# STM32H7B3 register map
File version: 3.3
CPU: CM7 r0p1, little endian, MPU, FPU, 4 interrupt priority bits
Registers are 32-bit, read-write, reset 0x0 unless marked. A register's access mark holds for its fields unless they carry their own. Offsets are from the block's base; [hi:lo] are bit positions; {n}, {i} and the like mark numbered series.

## CAN_CCU — FDCAN1
Base 0x4000A800
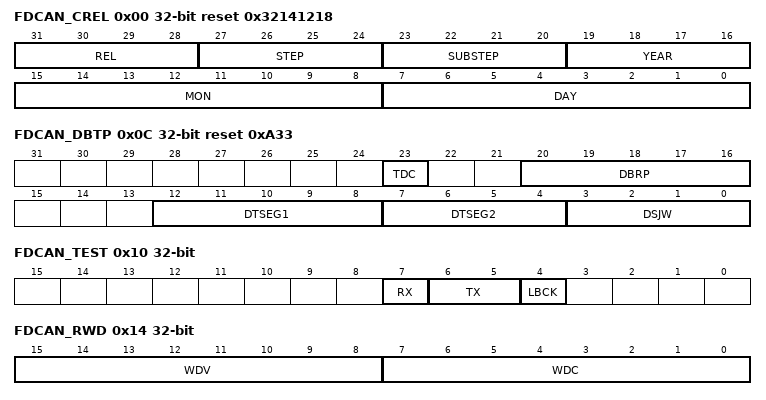
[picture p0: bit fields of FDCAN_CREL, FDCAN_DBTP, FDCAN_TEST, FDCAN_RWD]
0x00 FDCAN_CREL ro reset 0x32141218 — FDCAN Core Release Register
  [31:28] REL — Core release
  [27:24] STEP — Step of Core release
  [23:20] SUBSTEP — Sub-step of Core release
  [19:16] YEAR — Timestamp Year
  [15:8] MON — Timestamp Month
  [7:0] DAY — Timestamp Day
0x04 FDCAN_ENDN ro reset 0x87654321 — FDCAN Core Release Register
  [31:0] ETV — Endiannes Test Value
0x0C FDCAN_DBTP ro reset 0xA33 — FDCAN Data Bit Timing and Prescaler Register
  [23] TDC — Transceiver Delay Compensation
  [20:16] DBRP — Data BIt Rate Prescaler
  [12:8] DTSEG1 — Data time segment after sample point
  [7:4] DTSEG2 — Data time segment after sample point
  [3:0] DSJW — Synchronization Jump Width
0x10 FDCAN_TEST ro
  [7] RX — Control of Transmit Pin
  [6:5] TX — Loop Back mode
  [4] LBCK — Loop Back mode
0x14 FDCAN_RWD ro — FDCAN RAM Watchdog Register
  [15:8] WDV — Watchdog value
  [7:0] WDC — Watchdog configuration
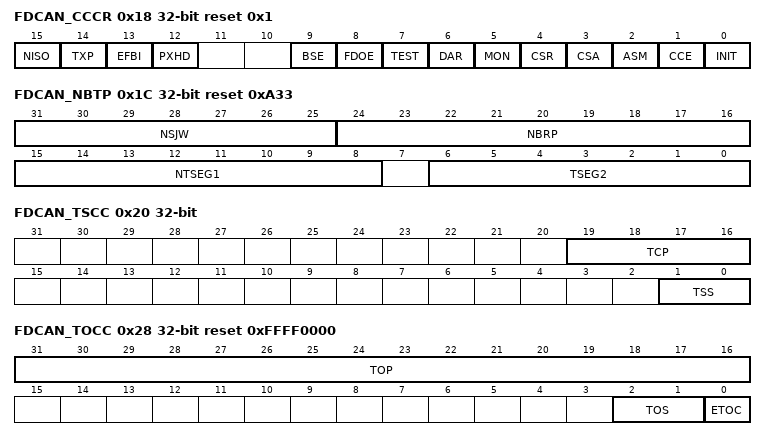
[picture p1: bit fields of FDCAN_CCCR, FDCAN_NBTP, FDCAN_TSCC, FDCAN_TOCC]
0x18 FDCAN_CCCR reset 0x1 — FDCAN CC Control Register
  [15] NISO — Non ISO Operation
  [14] TXP
  [13] EFBI — Edge Filtering during Bus Integration
  [12] PXHD — Protocol Exception Handling Disable
  [9] BSE — FDCAN Bit Rate Switching
  [8] FDOE — FD Operation Enable
  [7] TEST — Test Mode Enable
  [6] DAR — Disable Automatic Retransmission
  [5] MON — Bus Monitoring Mode
  [4] CSR — Clock Stop Request
  [3] CSA — Clock Stop Acknowledge
  [2] ASM — ASM Restricted Operation Mode
  [1] CCE — Configuration Change Enable
  [0] INIT — Initialization
0x1C FDCAN_NBTP reset 0xA33 — FDCAN Nominal Bit Timing and Prescaler Register
  [31:25] NSJW — NSJW: Nominal (Re)Synchronization Jump Width
  [24:16] NBRP — Bit Rate Prescaler
  [15:8] NTSEG1 — Nominal Time segment before sample point
  [6:0] TSEG2 — Nominal Time segment after sample point
0x20 FDCAN_TSCC — FDCAN Timestamp Counter Configuration Register
  [19:16] TCP — Timestamp Counter Prescaler
  [1:0] TSS — Timestamp Select
0x24 FDCAN_TSCV — FDCAN Timestamp Counter Value Register
  [15:0] TSC — Timestamp Counter
0x28 FDCAN_TOCC reset 0xFFFF0000 — FDCAN Timeout Counter Configuration Register
  [31:16] TOP — Timeout Period
  [2:1] TOS — Timeout Select
  [0] ETOC — Enable Timeout Counter
0x2C FDCAN_TOCV reset 0xFFFF — FDCAN Timeout Counter Value Register
  [15:0] TOC — Timeout Counter
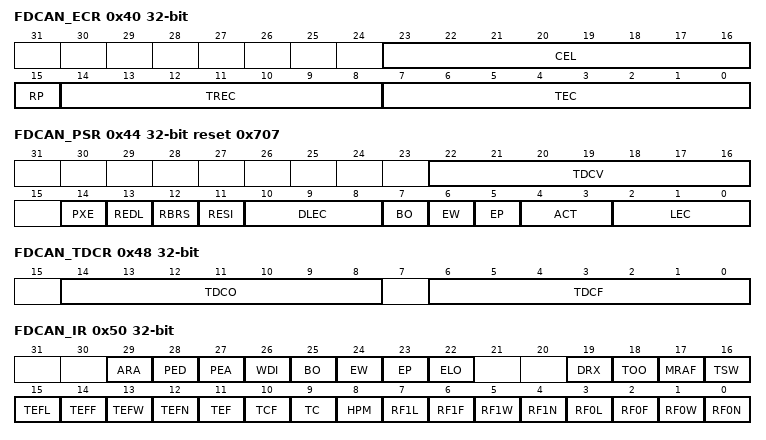
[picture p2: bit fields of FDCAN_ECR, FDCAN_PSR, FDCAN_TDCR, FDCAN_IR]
0x40 FDCAN_ECR — FDCAN Error Counter Register
  [23:16] CEL — AN Error Logging
  [15] RP — Receive Error Passive
  [14:8] TREC — Receive Error Counter
  [7:0] TEC — Transmit Error Counter
0x44 FDCAN_PSR reset 0x707 — FDCAN Protocol Status Register
  [22:16] TDCV — Transmitter Delay Compensation Value
  [14] PXE — Protocol Exception Event
  [13] REDL — Received FDCAN Message
  [12] RBRS — BRS flag of last received FDCAN Message
  [11] RESI — ESI flag of last received FDCAN Message
  [10:8] DLEC — Data Last Error Code
  [7] BO — Bus_Off Status
  [6] EW — Warning Status
  [5] EP — Error Passive
  [4:3] ACT — Activity
  [2:0] LEC — Last Error Code
0x48 FDCAN_TDCR ro — FDCAN Transmitter Delay Compensation Register
  [14:8] TDCO — Transmitter Delay Compensation Offset
  [6:0] TDCF — Transmitter Delay Compensation Filter Window Length
0x50 FDCAN_IR ro — FDCAN Interrupt Register
  [29] ARA — Access to Reserved Address
  [28] PED — Protocol Error in Data Phase (Data Bit Time is used)
  [27] PEA — Protocol Error in Arbitration Phase (Nominal Bit Time is used)
  [26] WDI — Watchdog Interrupt
  [25] BO — Bus_Off Status
  [24] EW — Warning Status
  [23] EP — Error Passive
  [22] ELO — Error Logging Overflow
  [19] DRX — Message stored to Dedicated Rx Buffer
  [18] TOO — Timeout Occurred
  [17] MRAF — Message RAM Access Failure
  [16] TSW — Timestamp Wraparound
  [15] TEFL — Tx Event FIFO Element Lost
  [14] TEFF — Tx Event FIFO Full
  [13] TEFW — Tx Event FIFO Watermark Reached
  [12] TEFN — Tx Event FIFO New Entry
  [11] TEF — Tx FIFO Empty
  [10] TCF — Transmission Cancellation Finished
  [9] TC — Transmission Completed
  [8] HPM — High Priority Message
  [7] RF1L — Rx FIFO 1 Message Lost
  [6] RF1F — Rx FIFO 1 Watermark Reached
  [5] RF1W — Rx FIFO 1 Watermark Reached
  [4] RF1N — Rx FIFO 1 New Message
  [3] RF0L — Rx FIFO 0 Message Lost
  [2] RF0F — Rx FIFO 0 Full
  [1] RF0W — Rx FIFO 0 Full
  [0] RF0N — Rx FIFO 0 New Message
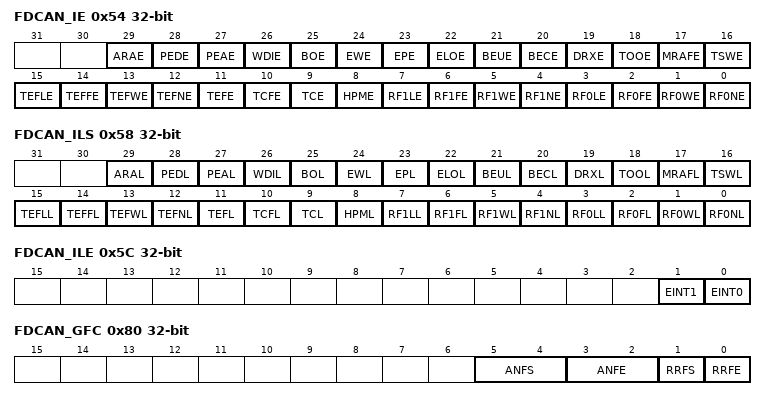
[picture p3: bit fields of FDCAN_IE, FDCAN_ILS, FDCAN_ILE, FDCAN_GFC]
0x54 FDCAN_IE — FDCAN Interrupt Enable Register
  [29] ARAE — Access to Reserved Address Enable
  [28] PEDE — Protocol Error in Data Phase Enable
  [27] PEAE — Protocol Error in Arbitration Phase Enable
  [26] WDIE — Watchdog Interrupt Enable
  [25] BOE — Bus_Off Status Enable
  [24] EWE — Warning Status Enable
  [23] EPE — Error Passive Enable
  [22] ELOE — Error Logging Overflow Enable
  [21] BEUE — Bit Error Uncorrected Interrupt Enable
  [20] BECE — Bit Error Corrected Interrupt Enable
  [19] DRXE — Message stored to Dedicated Rx Buffer Enable
  [18] TOOE — Timeout Occurred Enable
  [17] MRAFE — Message RAM Access Failure Enable
  [16] TSWE — Timestamp Wraparound Enable
  [15] TEFLE — Tx Event FIFO Element Lost Enable
  [14] TEFFE — Tx Event FIFO Full Enable
  [13] TEFWE — Tx Event FIFO Watermark Reached Enable
  [12] TEFNE — Tx Event FIFO New Entry Enable
  [11] TEFE — Tx FIFO Empty Enable
  [10] TCFE — Transmission Cancellation Finished Enable
  [9] TCE — Transmission Completed Enable
  [8] HPME — High Priority Message Enable
  [7] RF1LE — Rx FIFO 1 Message Lost Enable
  [6] RF1FE — Rx FIFO 1 Watermark Reached Enable
  [5] RF1WE — Rx FIFO 1 Watermark Reached Enable
  [4] RF1NE — Rx FIFO 1 New Message Enable
  [3] RF0LE — Rx FIFO 0 Message Lost Enable
  [2] RF0FE — Rx FIFO 0 Full Enable
  [1] RF0WE — Rx FIFO 0 Full Enable
  [0] RF0NE — Rx FIFO 0 New Message Enable
0x58 FDCAN_ILS ro — FDCAN Interrupt Line Select Register
  [29] ARAL — Access to Reserved Address Line
  [28] PEDL — Protocol Error in Data Phase Line
  [27] PEAL — Protocol Error in Arbitration Phase Line
  [26] WDIL — Watchdog Interrupt Line
  [25] BOL — Bus_Off Status
  [24] EWL — Warning Status Interrupt Line
  [23] EPL — Error Passive Interrupt Line
  [22] ELOL — Error Logging Overflow Interrupt Line
  [21] BEUL — Bit Error Uncorrected Interrupt Line
  [20] BECL — Bit Error Corrected Interrupt Line
  [19] DRXL — Message stored to Dedicated Rx Buffer Interrupt Line
  [18] TOOL — Timeout Occurred Interrupt Line
  [17] MRAFL — Message RAM Access Failure Interrupt Line
  [16] TSWL — Timestamp Wraparound Interrupt Line
  [15] TEFLL — Tx Event FIFO Element Lost Interrupt Line
  [14] TEFFL — Tx Event FIFO Full Interrupt Line
  [13] TEFWL — Tx Event FIFO Watermark Reached Interrupt Line
  [12] TEFNL — Tx Event FIFO New Entry Interrupt Line
  [11] TEFL — Tx FIFO Empty Interrupt Line
  [10] TCFL — Transmission Cancellation Finished Interrupt Line
  [9] TCL — Transmission Completed Interrupt Line
  [8] HPML — High Priority Message Interrupt Line
  [7] RF1LL — Rx FIFO 1 Message Lost Interrupt Line
  [6] RF1FL — Rx FIFO 1 Full Interrupt Line
  [5] RF1WL — Rx FIFO 1 Watermark Reached Interrupt Line
  [4] RF1NL — Rx FIFO 1 New Message Interrupt Line
  [3] RF0LL — Rx FIFO 0 Message Lost Interrupt Line
  [2] RF0FL — Rx FIFO 0 Full Interrupt Line
  [1] RF0WL — Rx FIFO 0 Watermark Reached Interrupt Line
  [0] RF0NL — Rx FIFO 0 New Message Interrupt Line
0x5C FDCAN_ILE — FDCAN Interrupt Line Enable Register
  [1] EINT1 — Enable Interrupt Line 1
  [0] EINT0 — Enable Interrupt Line 0
0x80 FDCAN_GFC — FDCAN Global Filter Configuration Register
  [5:4] ANFS — Accept Non-matching Frames Standard
  [3:2] ANFE — Accept Non-matching Frames Extended
  [1] RRFS — Reject Remote Frames Standard
  [0] RRFE — Reject Remote Frames Extended
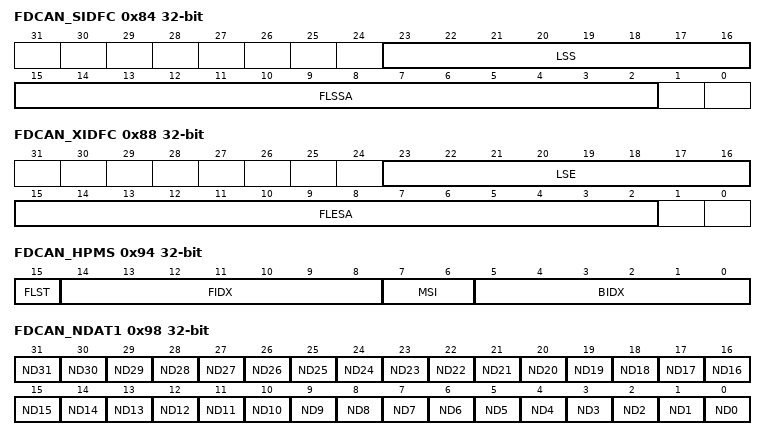
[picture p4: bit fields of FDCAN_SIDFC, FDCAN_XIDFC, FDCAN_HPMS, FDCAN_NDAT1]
0x84 FDCAN_SIDFC — FDCAN Standard ID Filter Configuration Register
  [23:16] LSS — List Size Standard
  [15:2] FLSSA — Filter List Standard Start Address
0x88 FDCAN_XIDFC — FDCAN Extended ID Filter Configuration Register
  [23:16] LSE — List Size Extended
  [15:2] FLESA — Filter List Standard Start Address
0x90 FDCAN_XIDAM — FDCAN Extended ID and Mask Register
  [28:0] EIDM — Extended ID Mask
0x94 FDCAN_HPMS ro — FDCAN High Priority Message Status Register
  [15] FLST — Filter List
  [14:8] FIDX — Filter Index
  [7:6] MSI — Message Storage Indicator
  [5:0] BIDX — Buffer Index
0x98 FDCAN_NDAT1 ro — FDCAN New Data 1 Register
  [n] ND{n} (n=0..31) — New data
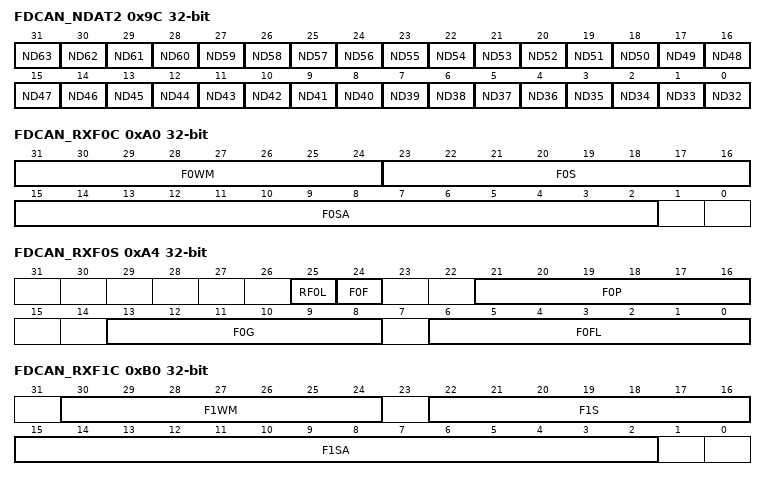
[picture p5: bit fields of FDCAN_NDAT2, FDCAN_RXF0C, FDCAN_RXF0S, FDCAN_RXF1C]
0x9C FDCAN_NDAT2 ro — FDCAN New Data 2 Register
  [n-32] ND{n} (n=32..63) — New data
0xA0 FDCAN_RXF0C — FDCAN Rx FIFO 0 Configuration Register
  [31:24] F0WM — FIFO 0 Watermark
  [23:16] F0S — Rx FIFO 0 Size
  [15:2] F0SA — Rx FIFO 0 Start Address
0xA4 FDCAN_RXF0S — FDCAN Rx FIFO 0 Status Register
  [25] RF0L — Rx FIFO 0 Message Lost
  [24] F0F — Rx FIFO 0 Full
  [21:16] F0P — Rx FIFO 0 Put Index
  [13:8] F0G — Rx FIFO 0 Get Index
  [6:0] F0FL — Rx FIFO 0 Fill Level
0xA8 FDCAN_RXF0A — CAN Rx FIFO 0 Acknowledge Register
  [5:0] FA01 — Rx FIFO 0 Acknowledge Index
0xAC FDCAN_RXBC — FDCAN Rx Buffer Configuration Register
  [15:2] RBSA — Rx Buffer Start Address
0xB0 FDCAN_RXF1C — FDCAN Rx FIFO 1 Configuration Register
  [30:24] F1WM — Rx FIFO 1 Watermark
  [22:16] F1S — Rx FIFO 1 Size
  [15:2] F1SA — Rx FIFO 1 Start Address
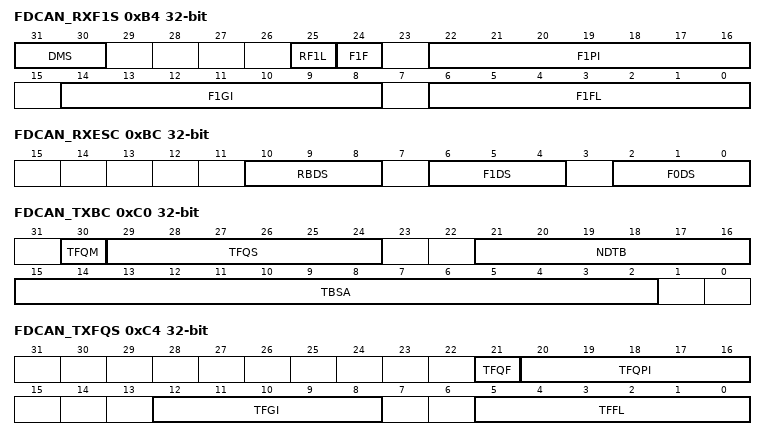
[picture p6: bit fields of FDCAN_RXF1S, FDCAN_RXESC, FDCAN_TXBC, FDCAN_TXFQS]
0xB4 FDCAN_RXF1S — FDCAN Rx FIFO 1 Status Register
  [31:30] DMS — Debug Message Status
  [25] RF1L — Rx FIFO 1 Message Lost
  [24] F1F — Rx FIFO 1 Full
  [22:16] F1PI — Rx FIFO 1 Put Index
  [14:8] F1GI — Rx FIFO 1 Get Index
  [6:0] F1FL — Rx FIFO 1 Fill Level
0xB8 FDCAN_RXF1A — FDCAN Rx FIFO 1 Acknowledge Register
  [5:0] F1AI — Rx FIFO 1 Acknowledge Index
0xBC FDCAN_RXESC — FDCAN Rx Buffer Element Size Configuration Register
  [10:8] RBDS — Rx Buffer Data Field Size:
  [6:4] F1DS — Rx FIFO 0 Data Field Size:
  [2:0] F0DS — Rx FIFO 1 Data Field Size:
0xC0 FDCAN_TXBC — FDCAN Tx Buffer Configuration Register
  [30] TFQM — Tx FIFO/Queue Mode
  [29:24] TFQS — Transmit FIFO/Queue Size
  [21:16] NDTB — Number of Dedicated Transmit Buffers
  [15:2] TBSA — Tx Buffers Start Address
0xC4 FDCAN_TXFQS ro — FDCAN Tx FIFO/Queue Status Register
  [21] TFQF — Tx FIFO/Queue Full
  [20:16] TFQPI — Tx FIFO/Queue Put Index
  [12:8] TFGI
  [5:0] TFFL — Tx FIFO Free Level
0xC8 FDCAN_TXESC — FDCAN Tx Buffer Element Size Configuration Register
  [2:0] TBDS — Tx Buffer Data Field Size:
0xCC FDCAN_TXBRP ro — FDCAN Tx Buffer Request Pending Register
  [31:0] TRP — Transmission Request Pending
0xD0 FDCAN_TXBAR — FDCAN Tx Buffer Add Request Register
  [31:0] AR — Add Request
0xD4 FDCAN_TXBCR — FDCAN Tx Buffer Cancellation Request Register
  [31:0] CR — Cancellation Request
0xD8 FDCAN_TXBTO — FDCAN Tx Buffer Transmission Occurred Register
  [31:0] TO — Transmission Occurred.
0xDC FDCAN_TXBCF ro — FDCAN Tx Buffer Cancellation Finished Register
  [31:0] CF — Cancellation Finished
0xE0 FDCAN_TXBTIE — FDCAN Tx Buffer Transmission Interrupt Enable Register
  [31:0] TIE — Transmission Interrupt Enable
0xE4 FDCAN_TXBCIE — FDCAN Tx Buffer Cancellation Finished Interrupt Enable Register
  [31:0] CF — Cancellation Finished Interrupt Enable
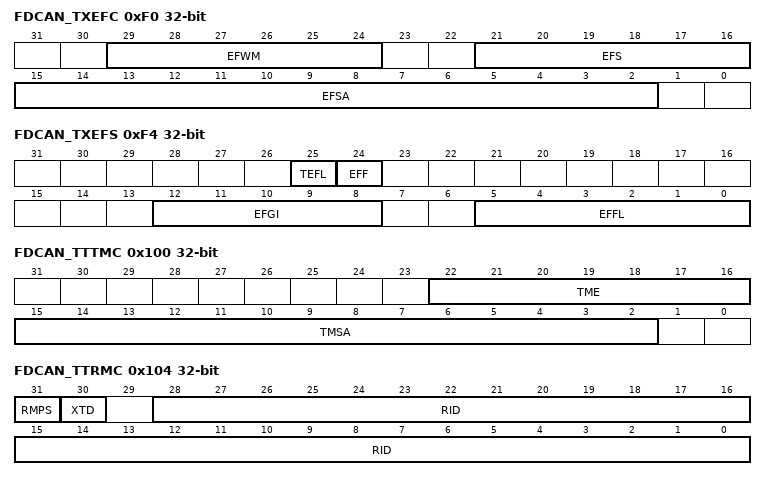
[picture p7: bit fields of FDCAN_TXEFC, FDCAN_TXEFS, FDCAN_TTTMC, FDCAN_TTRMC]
0xF0 FDCAN_TXEFC — FDCAN Tx Event FIFO Configuration Register
  [29:24] EFWM — Event FIFO Watermark
  [21:16] EFS — Event FIFO Size
  [15:2] EFSA — Event FIFO Start Address
0xF4 FDCAN_TXEFS — FDCAN Tx Event FIFO Status Register
  [25] TEFL — Tx Event FIFO Element Lost.
  [24] EFF — Event FIFO Full.
  [12:8] EFGI — Event FIFO Get Index.
  [5:0] EFFL — Event FIFO Fill Level
0xF8 FDCAN_TXEFA — FDCAN Tx Event FIFO Acknowledge Register
  [4:0] EFAI — Event FIFO Acknowledge Index
0x100 FDCAN_TTTMC — FDCAN TT Trigger Memory Configuration Register
  [22:16] TME — Trigger Memory Elements
  [15:2] TMSA — Trigger Memory Start Address
0x104 FDCAN_TTRMC — FDCAN TT Reference Message Configuration Register
  [31] RMPS — Reference Message Payload Select
  [30] XTD — Extended Identifier
  [28:0] RID — Reference Identifier.
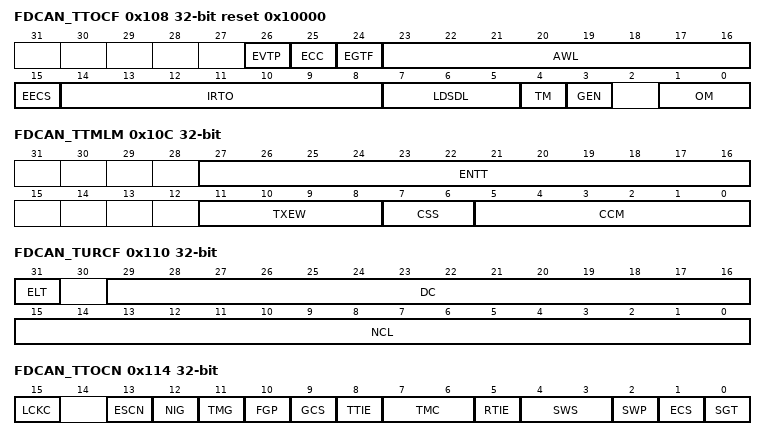
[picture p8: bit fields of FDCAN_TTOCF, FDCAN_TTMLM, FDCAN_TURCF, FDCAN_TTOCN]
0x108 FDCAN_TTOCF reset 0x10000 — FDCAN TT Operation Configuration Register
  [26] EVTP — Event Trigger Polarity
  [25] ECC — Enable Clock Calibration
  [24] EGTF — Enable Global Time Filtering
  [23:16] AWL — Application Watchdog Limit
  [15] EECS — Enable External Clock Synchronization
  [14:8] IRTO — Initial Reference Trigger Offset
  [7:5] LDSDL — LD of Synchronization Deviation Limit
  [4] TM — Time Master
  [3] GEN — Gap Enable
  [1:0] OM — Operation Mode
0x10C FDCAN_TTMLM — FDCAN TT Matrix Limits Register
  [27:16] ENTT — Expected Number of Tx Triggers
  [11:8] TXEW — Tx Enable Window
  [7:6] CSS — Cycle Start Synchronization
  [5:0] CCM — Cycle Count Max
0x110 FDCAN_TURCF — FDCAN TUR Configuration Register
  [31] ELT — Enable Local Time
  [29:16] DC — Denominator Configuration.
  [15:0] NCL — Numerator Configuration Low.
0x114 FDCAN_TTOCN — FDCAN TT Operation Control Register
  [15] LCKC — TT Operation Control Register Locked
  [13] ESCN — External Synchronization Control
  [12] NIG — Next is Gap
  [11] TMG — Time Mark Gap
  [10] FGP — Finish Gap.
  [9] GCS — Gap Control Select
  [8] TTIE — Trigger Time Mark Interrupt Pulse Enable
  [7:6] TMC — Register Time Mark Compare
  [5] RTIE — Register Time Mark Interrupt Pulse Enable
  [4:3] SWS — Stop Watch Source.
  [2] SWP — Stop Watch Polarity
  [1] ECS — External Clock Synchronization
  [0] SGT — Set Global time
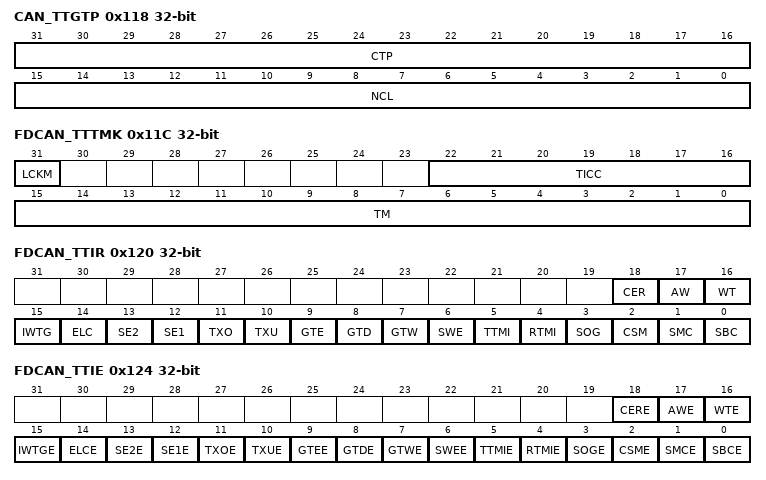
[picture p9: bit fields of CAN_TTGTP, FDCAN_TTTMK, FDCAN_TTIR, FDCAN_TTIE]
0x118 CAN_TTGTP — FDCAN TT Global Time Preset Register
  [31:16] CTP — Cycle Time Target Phase
  [15:0] NCL — Time Preset
0x11C FDCAN_TTTMK — FDCAN TT Time Mark Register
  [31] LCKM — TT Time Mark Register Locked
  [22:16] TICC — Time Mark Cycle Code
  [15:0] TM — Time Mark
0x120 FDCAN_TTIR — FDCAN TT Interrupt Register
  [18] CER — Configuration Error
  [17] AW — Application Watchdog
  [16] WT — Watch Trigger
  [15] IWTG — Initialization Watch Trigger
  [14] ELC — Error Level Changed.
  [13] SE2 — Scheduling Error 2
  [12] SE1 — Scheduling Error 1
  [11] TXO — Tx Count Overflow
  [10] TXU — Tx Count Underflow
  [9] GTE — Global Time Error
  [8] GTD — Global Time Discontinuity
  [7] GTW — Global Time Wrap
  [6] SWE — Stop Watch Event
  [5] TTMI — Trigger Time Mark Event Internal
  [4] RTMI — Register Time Mark Interrupt.
  [3] SOG — Start of Gap
  [2] CSM — Change of Synchronization Mode
  [1] SMC — Start of Matrix Cycle
  [0] SBC — Start of Basic Cycle
0x124 FDCAN_TTIE — FDCAN TT Interrupt Enable Register
  [18] CERE — Configuration Error Interrupt Enable
  [17] AWE — Application Watchdog Interrupt Enable
  [16] WTE — Watch Trigger Interrupt Enable
  [15] IWTGE — Initialization Watch Trigger Interrupt Enable
  [14] ELCE — Change Error Level Interrupt Enable
  [13] SE2E — Scheduling Error 2 Interrupt Enable
  [12] SE1E — Scheduling Error 1 Interrupt Enable
  [11] TXOE — Tx Count Overflow Interrupt Enable
  [10] TXUE — Tx Count Underflow Interrupt Enable
  [9] GTEE — Global Time Error Interrupt Enable
  [8] GTDE — Global Time Discontinuity Interrupt Enable
  [7] GTWE — Global Time Wrap Interrupt Enable
  [6] SWEE — Stop Watch Event Interrupt Enable
  [5] TTMIE — Trigger Time Mark Event Internal Interrupt Enable
  [4] RTMIE — Register Time Mark Interrupt Enable
  [3] SOGE — Start of Gap Interrupt Enable
  [2] CSME — Change of Synchronization Mode Interrupt Enable
  [1] SMCE — Start of Matrix Cycle Interrupt Enable
  [0] SBCE — Start of Basic Cycle Interrupt Enable
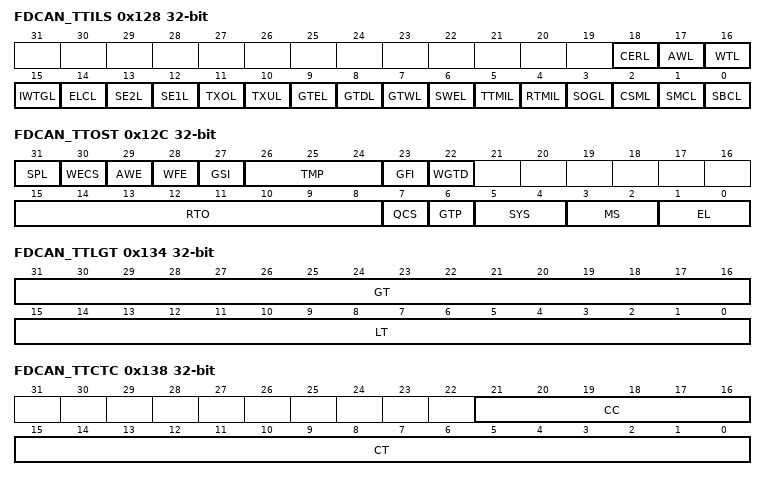
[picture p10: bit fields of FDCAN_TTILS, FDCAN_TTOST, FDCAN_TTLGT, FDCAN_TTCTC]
0x128 FDCAN_TTILS — FDCAN TT Interrupt Line Select Register
  [18] CERL — Configuration Error Interrupt Line
  [17] AWL — Application Watchdog Interrupt Line
  [16] WTL — Watch Trigger Interrupt Line
  [15] IWTGL — Initialization Watch Trigger Interrupt Line
  [14] ELCL — Change Error Level Interrupt Line
  [13] SE2L — Scheduling Error 2 Interrupt Line
  [12] SE1L — Scheduling Error 1 Interrupt Line
  [11] TXOL — Tx Count Overflow Interrupt Line
  [10] TXUL — Tx Count Underflow Interrupt Line
  [9] GTEL — Global Time Error Interrupt Line
  [8] GTDL — Global Time Discontinuity Interrupt Line
  [7] GTWL — Global Time Wrap Interrupt Line
  [6] SWEL — Stop Watch Event Interrupt Line
  [5] TTMIL — Trigger Time Mark Event Internal Interrupt Line
  [4] RTMIL — Register Time Mark Interrupt Line
  [3] SOGL — Start of Gap Interrupt Line
  [2] CSML — Change of Synchronization Mode Interrupt Line
  [1] SMCL — Start of Matrix Cycle Interrupt Line
  [0] SBCL — Start of Basic Cycle Interrupt Line
0x12C FDCAN_TTOST ro — FDCAN TT Operation Status Register
  [31] SPL — Schedule Phase Lock
  [30] WECS — Wait for External Clock Synchronization
  [29] AWE — Application Watchdog Event
  [28] WFE — Wait for Event
  [27] GSI — Gap Started Indicator.
  [26:24] TMP — Time Master Priority
  [23] GFI — Gap Finished Indicator.
  [22] WGTD — Wait for Global Time Discontinuity
  [15:8] RTO — Reference Trigger Offset
  [7] QCS — Quality of Clock Speed
  [6] GTP — Quality of Global Time Phase
  [5:4] SYS — Synchronization State
  [3:2] MS — Master State.
  [1:0] EL — Error Level
0x130 FDCAN_TURNA ro — FDCAN TUR Numerator Actual Register
  [17:0] NAV — Numerator Actual Value
0x134 FDCAN_TTLGT ro — FDCAN TT Local and Global Time Register
  [31:16] GT — Global Time
  [15:0] LT — Local Time
0x138 FDCAN_TTCTC ro — FDCAN TT Cycle Time and Count Register
  [21:16] CC — Cycle Count
  [15:0] CT — Cycle Time
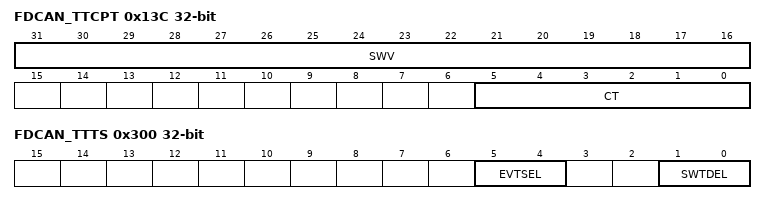
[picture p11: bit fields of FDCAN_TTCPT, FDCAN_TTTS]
0x13C FDCAN_TTCPT ro — FDCAN TT Capture Time Register
  [31:16] SWV — Stop Watch Value
  [5:0] CT — Cycle Count Value
0x140 FDCAN_TTCSM ro — FDCAN TT Cycle Sync Mark Register
  [15:0] CSM — Cycle Sync Mark
0x300 FDCAN_TTTS — FDCAN TT Trigger Select Register
  [5:4] EVTSEL — Event trigger input selection
  [1:0] SWTDEL — Stop watch trigger input selection

## TT_FDCAN — FDCAN1
Base 0x4000A000
Registers as CAN_CCU; these are added or differ:
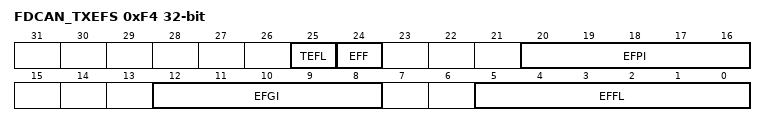
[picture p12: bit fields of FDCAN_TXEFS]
0xF4 FDCAN_TXEFS — FDCAN Tx Event FIFO Status Register
  [25] TEFL — Tx Event FIFO Element Lost.
  [24] EFF — Event FIFO Full.
  [20:16] EFPI — Event FIFO put index.
  [12:8] EFGI — Event FIFO Get Index.
  [5:0] EFFL — Event FIFO Fill Level
